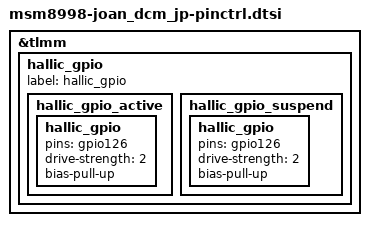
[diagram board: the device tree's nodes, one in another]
/* Copyright (c) 2015-2016, The Linux Foundation. All rights reserved.
 *
 * This program is free software; you can redistribute it and/or modify
 * it under the terms of the GNU General Public License version 2 and
 * only version 2 as published by the Free Software Foundation.
 *
 * This program is distributed in the hope that it will be useful,
 * but WITHOUT ANY WARRANTY; without even the implied warranty of
 * MERCHANTABILITY or FITNESS FOR A PARTICULAR PURPOSE.  See the
 * GNU General Public License for more details.
 */

#include "../msm8998-joan-common/msm8998-joan-common-pinctrl.dtsi"

&tlmm {

	/* pin set for Hall IC */
	hallic_gpio {
		label = "hallic_gpio";
		hallic_gpio_active: hallic_gpio_active {
			hallic_gpio {
				pins = "gpio126";
				drive-strength = <2>;
				bias-pull-up;
			};
		};
		hallic_gpio_suspend: hallic_gpio_suspend {
			hallic_gpio {
				pins = "gpio126";
				drive-strength = <2>;
				bias-pull-up;
			};
		};
	};
};
